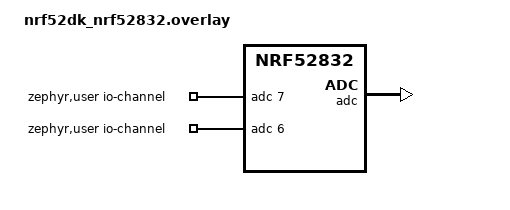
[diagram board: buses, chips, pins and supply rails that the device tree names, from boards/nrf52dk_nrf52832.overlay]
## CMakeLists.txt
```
# SPDX-License-Identifier: Apache-2.0

cmake_minimum_required(VERSION 3.20.0)

find_package(Zephyr REQUIRED HINTS $ENV{ZEPHYR_BASE})
project(nrf52_learning)

target_sources(app PRIVATE src/main.c)

target_sources(app PRIVATE components/my_gpio/my_gpio.c)
target_include_directories(app PRIVATE components/my_gpio)

target_sources(app PRIVATE components/uart0/uart0.c)
target_include_directories(app PRIVATE components/uart0)

target_sources(app PRIVATE components/uart1/uart1.c)
target_include_directories(app PRIVATE components/uart1)

target_sources(app PRIVATE components/usb/usb.c)
target_include_directories(app PRIVATE components/usb)
```

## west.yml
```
manifest:
  self:
    path: application
  remotes:
    - name: sdk
      url-base: https://github.com/nrfconnect
  projects:
    - name: sdk-nrf
      remote: sdk
      path: nrf
      revision: v2.4.0
      import:
        path-prefix: external
      clone-depth: 1
```

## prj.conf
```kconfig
CONFIG_SERIAL=y
CONFIG_LOG=y
CONFIG_LOG_MODE_IMMEDIATE=y


#USB CONFIG
CONFIG_USB_DEVICE_STACK=y
CONFIG_USB_DEVICE_PRODUCT="Zephyr test"
CONFIG_USB_DEVICE_PID=0x0004
CONFIG_USB_DEVICE_MANUFACTURER="Nordic Semiconductor"
CONFIG_USB_DEVICE_VID=0x1915
CONFIG_USB_DEVICE_INITIALIZE_AT_BOOT=n
CONFIG_SERIAL=y
CONFIG_CONSOLE=y
CONFIG_UART_CONSOLE=y



#UART CONFIG
CONFIG_UART_ASYNC_API=y #Requires for UART1 and UART2
CONFIG_UART_INTERRUPT_DRIVEN=y #Requires for USB_CDC_ACM



#UART0 CONFIG
CONFIG_UART_0_INTERRUPT_DRIVEN=n
CONFIG_UART_0_ASYNC=y
CONFIG_UART_0_NRF_HW_ASYNC=y
CONFIG_UART_0_NRF_HW_ASYNC_TIMER=3
CONFIG_UART_1_NRF_ASYNC_LOW_POWER=y
CONFIG_NRFX_TIMER3=y

#UART1 CONFIG2
CONFIG_UART_1_INTERRUPT_DRIVEN=n
CONFIG_UART_1_ASYNC=y
CONFIG_UART_1_NRF_HW_ASYNC=y
CONFIG_UART_1_NRF_HW_ASYNC_TIMER=2
CONFIG_UART_1_NRF_ASYNC_LOW_POWER=y
CONFIG_NRFX_TIMER2=y

#POWER MANAGEMENT
CONFIG_POWEROFF=y
CONFIG_PM_DEVICE=y







#If you want to use RTT for logging, enable the following lines
#START OF RTT CONFIGURATION
# CONFIG_USE_SEGGER_RTT=y
# CONFIG_LOG_BACKEND_RTT=y
# CONFIG_LOG_BACKEND_UART=n
# CONFIG_LOG_PRINTK=n
#END OF RTT CONFIGURATION
```

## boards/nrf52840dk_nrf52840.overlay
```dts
arduino_serial: &uart1 {
	status = "okay";
};


/ {
	chosen {
		zephyr,console = &cdc_acm_uart0;
	};
};

&zephyr_udc0 {
	cdc_acm_uart0: cdc_acm_uart0 {
		compatible = "zephyr,cdc-acm-uart";
		label = "CDC_ACM_0";
	};
};





// &uart1 {
// 	status = "okay";
// 	pinctrl-0 = <&uart1_default_alt>;
// 	pinctrl-1 = <&uart1_sleep_alt>;
// 	pinctrl-names = "default", "sleep";
// 	lpuart: nrf-sw-lpuart {
// 		compatible = "nordic,nrf-sw-lpuart";
// 		status = "okay";
// 		req-pin = <46>;
// 		rdy-pin = <47>;
// 	};
// };

// &uart0 {
// 	disable-rx;
// };
```

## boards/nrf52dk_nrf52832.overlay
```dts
/{
    zephyr,user{
        io-channels = <&adc 7>, <&adc 6>;
    };
};

&adc {
    status = "okay";
};
```

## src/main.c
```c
/*
 * Copyright (c) 2012-2014 Wind River Systems, Inc.
 *
 * SPDX-License-Identifier: Apache-2.0
 */

#include <zephyr/kernel.h>
#include <zephyr/drivers/gpio.h>
#include <zephyr/sys/poweroff.h>


#include "stdio.h"
#include "my_gpio.h"
#include "uart0.h"
#include "uart1.h"
#include "usb.h"


BUILD_ASSERT(DT_NODE_HAS_COMPAT(DT_CHOSEN(zephyr_console), zephyr_cdc_acm_uart),
			 "Console device is not ACM CDC UART device");


#define LOG_LEVEL 4
#include <zephyr/logging/log.h>
LOG_MODULE_REGISTER(nrf52_learning);

#define STACKSIZE 1024

 K_THREAD_DEFINE(uart0_parser, STACKSIZE, uart0_parser_thread, NULL, NULL, NULL, 7, 0, 0);
 K_THREAD_DEFINE(uart1_parser, STACKSIZE, uart1_parser_thread, NULL, NULL, NULL, 7, 0, 0);





int main(void)
{





	app_usb_init();
	app_uart0_init();
	app_uart1_init();

	while (1)
	{
		uart1_send_string("Hello from UART1\n");
		uart0_send_string("Hello from UART0\n");
		k_sleep(K_MSEC(1000));
	}
}
```
